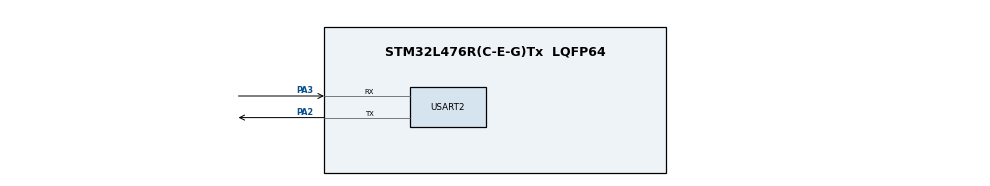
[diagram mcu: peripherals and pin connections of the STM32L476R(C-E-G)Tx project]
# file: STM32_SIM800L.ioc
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Mcu.Family=STM32L4
Mcu.Name=STM32L476R(C-E-G)Tx
Mcu.Package=LQFP64
NVIC.PriorityGroup=NVIC_PRIORITYGROUP_4
NVIC.USART2_IRQn=true\:0\:0\:false\:false\:true\:true\:true
PA13\ (JTMS-SWDIO).Mode=Serial_Wire
PA13\ (JTMS-SWDIO).Signal=SYS_JTMS-SWDIO
PA14\ (JTCK-SWCLK).Mode=Serial_Wire
PA14\ (JTCK-SWCLK).Signal=SYS_JTCK-SWCLK
PA2.Mode=Asynchronous
PA2.Signal=USART2_TX
PA3.Mode=Asynchronous
PA3.Signal=USART2_RX
ProjectManager.HeapSize=0x200
ProjectManager.StackSize=0x400
ProjectManager.TargetToolchain=STM32CubeIDE
RCC.HSE_VALUE=8000000
RCC.HSI_VALUE=16000000
RCC.LSE_VALUE=32768
RCC.MSI_VALUE=4000000
RCC.VCOOutputFreq_Value=32000000
USART2.VirtualMode-Asynchronous=VM_ASYNC
board=custom

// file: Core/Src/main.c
/* USER CODE BEGIN Header */
/**
  ******************************************************************************
  * @file           : main.c
  * @brief          : Main program body
  ******************************************************************************
  * @attention
  *
  * <h2><center>&copy; Copyright (c) 2020 STMicroelectronics.
  * All rights reserved.</center></h2>
  *
  * This software component is licensed by ST under BSD 3-Clause license,
  * the "License"; You may not use this file except in compliance with the
  * License. You may obtain a copy of the License at:
  *                        opensource.org/licenses/BSD-3-Clause
  *
  ******************************************************************************
  */
/* USER CODE END Header */
#include "main.h"
#include "stdio.h"

/* USER CODE BEGIN Includes */
#include "MQTTSim800.h"
/* USER CODE END Includes */

UART_HandleTypeDef huart2;

/* USER CODE BEGIN PV */
SIM800_t SIM800;
/* USER CODE END PV */

void SystemClock_Config(void);
static void MX_GPIO_Init(void);
static void MX_USART2_UART_Init(void);

/* USER CODE BEGIN 0 */
	void HAL_UART_RxCpltCallback(UART_HandleTypeDef * huart) {
    if (huart == UART_SIM800) {
        Sim800_RxCallBack();
    }
}
/* USER CODE END 0 */

int main(void)
{

  /* MCU Configuration--------------------------------------------------------*/

  /* Reset of all peripherals, Initializes the Flash interface and the Systick. */
  HAL_Init();

  /* Configure the system clock */
  SystemClock_Config();

  /* Initialize all configured peripherals */
  MX_GPIO_Init();
  MX_USART2_UART_Init();
  /* USER CODE BEGIN 2 */
  	  SIM800.sim.apn = "wireless.twilio.com";
      SIM800.sim.apn_user = " ";
      SIM800.sim.apn_pass = " ";
      SIM800.mqttServer.host = "45.17.141.18";
      SIM800.mqttServer.port = 1883;
      SIM800.mqttClient.username = "";
      SIM800.mqttClient.pass = "";
      SIM800.mqttClient.clientID = "STM32_mqtt";
      SIM800.mqttClient.keepAliveInterval = 120;

      MQTT_Init();

      uint8_t sub = 0;
  /* USER CODE END 2 */

  /* Infinite loop */
  /* USER CODE BEGIN WHILE */
  while (1)
  {
	  if (SIM800.mqttServer.connect == 0) {
	           MQTT_Init();
	           sub = 0;
	       }
	       if (SIM800.mqttServer.connect == 1) {
	           if(sub == 0){
	               MQTT_Sub("test");
	               sub = 1;
	           }
	           MQTT_Pub("Device1", "test");

	           if(SIM800.mqttReceive.newEvent) {
	               unsigned char *topic = SIM800.mqttReceive.topic;
	               char* payload = SIM800.mqttReceive.payload;
	               SIM800.mqttReceive.newEvent = 0;
	               printf("%payload",payload);
	           }

	       }
	       HAL_Delay(1000);
    /* USER CODE END WHILE */

  }
}

void SystemClock_Config(void)
{
  RCC_OscInitTypeDef RCC_OscInitStruct = {0};
  RCC_ClkInitTypeDef RCC_ClkInitStruct = {0};
  RCC_PeriphCLKInitTypeDef PeriphClkInit = {0};

  /** Initializes the RCC Oscillators according to the specified parameters
  * in the RCC_OscInitTypeDef structure.
  */
  RCC_OscInitStruct.OscillatorType = RCC_OSCILLATORTYPE_MSI;
  RCC_OscInitStruct.MSIState = RCC_MSI_ON;
  RCC_OscInitStruct.MSICalibrationValue = 0;
  RCC_OscInitStruct.MSIClockRange = RCC_MSIRANGE_6;
  RCC_OscInitStruct.PLL.PLLState = RCC_PLL_NONE;
  if (HAL_RCC_OscConfig(&RCC_OscInitStruct) != HAL_OK)
  {
    Error_Handler();
  }
  /** Initializes the CPU, AHB and APB buses clocks
  */
  RCC_ClkInitStruct.ClockType = RCC_CLOCKTYPE_HCLK|RCC_CLOCKTYPE_SYSCLK
                              |RCC_CLOCKTYPE_PCLK1|RCC_CLOCKTYPE_PCLK2;
  RCC_ClkInitStruct.SYSCLKSource = RCC_SYSCLKSOURCE_MSI;
  RCC_ClkInitStruct.AHBCLKDivider = RCC_SYSCLK_DIV1;
  RCC_ClkInitStruct.APB1CLKDivider = RCC_HCLK_DIV1;
  RCC_ClkInitStruct.APB2CLKDivider = RCC_HCLK_DIV1;

  if (HAL_RCC_ClockConfig(&RCC_ClkInitStruct, FLASH_LATENCY_0) != HAL_OK)
  {
    Error_Handler();
  }
  PeriphClkInit.PeriphClockSelection = RCC_PERIPHCLK_USART2;
  PeriphClkInit.Usart2ClockSelection = RCC_USART2CLKSOURCE_PCLK1;
  if (HAL_RCCEx_PeriphCLKConfig(&PeriphClkInit) != HAL_OK)
  {
    Error_Handler();
  }
  /** Configure the main internal regulator output voltage
  */
  if (HAL_PWREx_ControlVoltageScaling(PWR_REGULATOR_VOLTAGE_SCALE1) != HAL_OK)
  {
    Error_Handler();
  }
}

static void MX_USART2_UART_Init(void)
{

  huart2.Instance = USART2;
  huart2.Init.BaudRate = 115200;
  huart2.Init.WordLength = UART_WORDLENGTH_8B;
  huart2.Init.StopBits = UART_STOPBITS_1;
  huart2.Init.Parity = UART_PARITY_NONE;
  huart2.Init.Mode = UART_MODE_TX_RX;
  huart2.Init.HwFlowCtl = UART_HWCONTROL_NONE;
  huart2.Init.OverSampling = UART_OVERSAMPLING_16;
  huart2.Init.OneBitSampling = UART_ONE_BIT_SAMPLE_DISABLE;
  huart2.AdvancedInit.AdvFeatureInit = UART_ADVFEATURE_NO_INIT;
  if (HAL_UART_Init(&huart2) != HAL_OK)
  {
    Error_Handler();
  }

}

static void MX_GPIO_Init(void)
{

  /* GPIO Ports Clock Enable */
  __HAL_RCC_GPIOA_CLK_ENABLE();

}

void Error_Handler(void)
{
}

/************************ (C) COPYRIGHT STMicroelectronics *****END OF FILE****/
